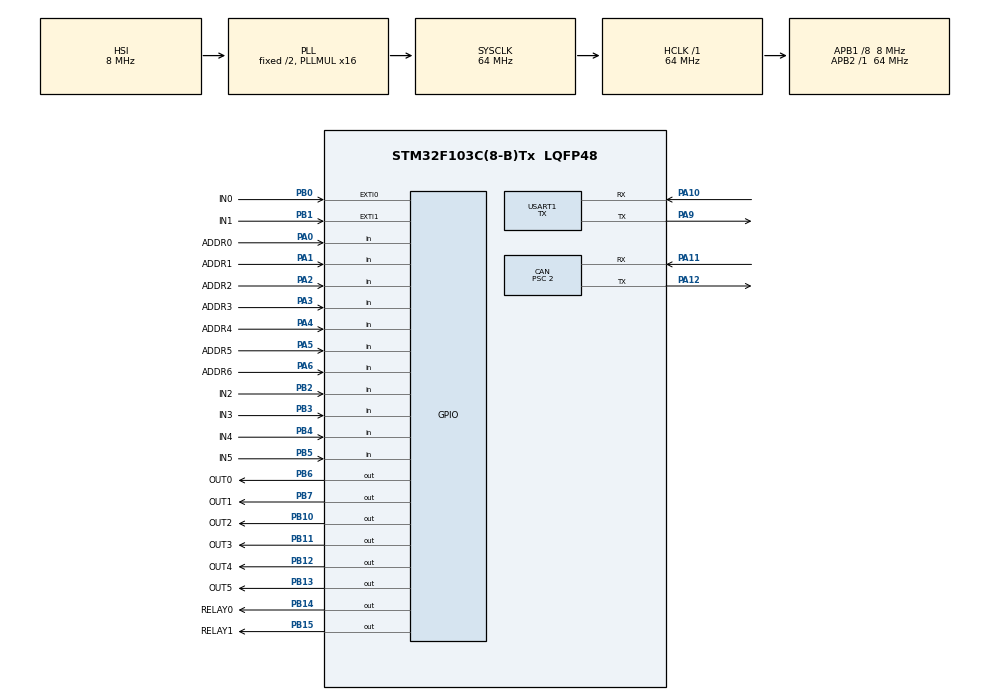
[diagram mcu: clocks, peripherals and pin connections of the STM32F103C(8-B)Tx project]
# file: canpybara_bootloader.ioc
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CAN.ABOM=ENABLE
CAN.BS1=CAN_BS1_6TQ
CAN.BS2=CAN_BS2_1TQ
CAN.CalculateTimeBit=2000
CAN.CalculateTimeQuantum=250.0
CAN.Prescaler=2
IWDG.Prescaler=IWDG_PRESCALER_16
Mcu.Family=STM32F1
Mcu.Name=STM32F103C(8-B)Tx
Mcu.Package=LQFP48
NVIC.CAN1_RX1_IRQn=true\:0\:0\:false\:false\:true\:true\:true
NVIC.CAN1_SCE_IRQn=true\:0\:0\:false\:false\:true\:true\:true
NVIC.EXTI0_IRQn=true\:0\:0\:false\:false\:true\:true\:true
NVIC.EXTI1_IRQn=true\:0\:0\:false\:false\:true\:true\:true
NVIC.PriorityGroup=NVIC_PRIORITYGROUP_4
NVIC.RCC_IRQn=true\:0\:0\:false\:false\:true\:true\:false
NVIC.USB_HP_CAN1_TX_IRQn=true\:0\:0\:false\:false\:true\:true\:true
NVIC.USB_LP_CAN1_RX0_IRQn=true\:0\:0\:false\:false\:true\:true\:true
PA0-WKUP.GPIO_Label=ADDR0
PA0-WKUP.GPIO_PuPd=GPIO_PULLUP
PA0-WKUP.Signal=GPIO_Input
PA1.GPIO_Label=ADDR1
PA1.GPIO_PuPd=GPIO_PULLUP
PA1.Signal=GPIO_Input
PA10.Mode=Asynchronous
PA10.Signal=USART1_RX
PA11.Mode=Master
PA11.Signal=CAN_RX
PA12.Mode=Master
PA12.Signal=CAN_TX
PA13.Mode=Serial_Wire
PA13.Signal=SYS_JTMS-SWDIO
PA14.Mode=Serial_Wire
PA14.Signal=SYS_JTCK-SWCLK
PA2.GPIO_Label=ADDR2
PA2.GPIO_PuPd=GPIO_PULLUP
PA2.Signal=GPIO_Input
PA3.GPIO_Label=ADDR3
PA3.GPIO_PuPd=GPIO_PULLUP
PA3.Signal=GPIO_Input
PA4.GPIO_Label=ADDR4
PA4.GPIO_PuPd=GPIO_PULLUP
PA4.Signal=GPIO_Input
PA5.GPIO_Label=ADDR5
PA5.GPIO_PuPd=GPIO_PULLUP
PA5.Signal=GPIO_Input
PA6.GPIO_Label=ADDR6
PA6.GPIO_PuPd=GPIO_PULLUP
PA6.Signal=GPIO_Input
PA9.Mode=Asynchronous
PA9.Signal=USART1_TX
PB0.GPIO_Label=IN0
PB0.GPIO_ModeDefaultEXTI=GPIO_MODE_IT_FALLING
PB0.Signal=GPXTI0
PB1.GPIO_Label=IN1
PB1.GPIO_ModeDefaultEXTI=GPIO_MODE_IT_FALLING
PB1.Signal=GPXTI1
PB10.GPIO_Label=OUT2
PB10.Signal=GPIO_Output
PB11.GPIO_Label=OUT3
PB11.Signal=GPIO_Output
PB12.GPIO_Label=OUT4
PB12.Signal=GPIO_Output
PB13.GPIO_Label=OUT5
PB13.Signal=GPIO_Output
PB14.GPIO_Label=RELAY0
PB14.Signal=GPIO_Output
PB15.GPIO_Label=RELAY1
PB15.Signal=GPIO_Output
PB2.GPIO_Label=IN2
PB2.Signal=GPIO_Input
PB3.GPIO_Label=IN3
PB3.Signal=GPIO_Input
PB4.GPIO_Label=IN4
PB4.Signal=GPIO_Input
PB5.GPIO_Label=IN5
PB5.Signal=GPIO_Input
PB6.GPIO_Label=OUT0
PB6.Signal=GPIO_Output
PB7.GPIO_Label=OUT1
PB7.Signal=GPIO_Output
PB8.Signal=I2C1_SCL
PB9.Signal=I2C1_SDA
PD0-OSC_IN.Mode=HSE-External-Oscillator
PD0-OSC_IN.Signal=RCC_OSC_IN
PD1-OSC_OUT.Mode=HSE-External-Oscillator
PD1-OSC_OUT.Signal=RCC_OSC_OUT
ProjectManager.HeapSize=0x200
ProjectManager.StackSize=0x400
ProjectManager.TargetToolchain=Makefile
RCC.AHBFreq_Value=64000000
RCC.APB1CLKDivider=RCC_HCLK_DIV8
RCC.APB1Freq_Value=8000000
RCC.APB1TimFreq_Value=16000000
RCC.APB2Freq_Value=64000000
RCC.APB2TimFreq_Value=64000000
RCC.HCLKFreq_Value=64000000
RCC.PLLMUL=RCC_PLL_MUL16
RCC.SYSCLKFreq_VALUE=64000000
RCC.SYSCLKSource=RCC_SYSCLKSOURCE_PLLCLK
RCC.USBFreq_Value=64000000
USART1.Mode=MODE_TX
USART1.VirtualMode=VM_ASYNC
VP_IWDG_VS_IWDG.Mode=IWDG_Activate
board=custom

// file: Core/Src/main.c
/* USER CODE BEGIN Header */
/**
  ******************************************************************************
  * @file           : main.c
  * @brief          : Main program body
  ******************************************************************************
  * @attention
  *
  * <h2><center>&copy; Copyright (c) 2020 STMicroelectronics.
  * All rights reserved.</center></h2>
  *
  * This software component is licensed by ST under BSD 3-Clause license,
  * the "License"; You may not use this file except in compliance with the
  * License. You may obtain a copy of the License at:
  *                        opensource.org/licenses/BSD-3-Clause
  *
  ******************************************************************************
  */
/* USER CODE END Header */

#include "main.h"

/* USER CODE BEGIN Includes */

#include "logger.h"
#include "can.h"
#include "bootloader.h"

/* USER CODE END Includes */

CAN_HandleTypeDef hcan;

IWDG_HandleTypeDef hiwdg;

UART_HandleTypeDef huart1;

/* USER CODE BEGIN PV */
/* Private variables ---------------------------------------------------------*/

/* USER CODE END PV */

void SystemClock_Config(void);
static void MX_GPIO_Init(void);
static void MX_CAN_Init(void);
static void MX_USART1_UART_Init(void);
static void MX_IWDG_Init(void);
/* USER CODE BEGIN PFP */
/* Private function prototypes -----------------------------------------------*/

/* USER CODE END PFP */

int main(void)
{

  /* MCU Configuration--------------------------------------------------------*/

  /* Reset of all peripherals, Initializes the Flash interface and the Systick. */
  HAL_Init();

  /* Configure the system clock */
  SystemClock_Config();

  /* Initialize all configured peripherals */
  MX_GPIO_Init();
  MX_CAN_Init();
  MX_USART1_UART_Init();
  MX_IWDG_Init();
  /* USER CODE BEGIN 2 */

  LOG_BOOT();

  canpybara_can_init();

  HAL_Delay(1000);

  canpybara_bootloader_send_discovery();
  /* USER CODE END 2 */

  /* Infinite loop */
  /* USER CODE BEGIN WHILE */
  for(;;)
  {
    HAL_IWDG_Refresh(&hiwdg);
    __asm__("WFI");

    canpybara_bootloader_loop();
    /* USER CODE END WHILE */

  }
}

void SystemClock_Config(void)
{
  RCC_OscInitTypeDef RCC_OscInitStruct = {0};
  RCC_ClkInitTypeDef RCC_ClkInitStruct = {0};

  /** Initializes the CPU, AHB and APB busses clocks
  */
  RCC_OscInitStruct.OscillatorType = RCC_OSCILLATORTYPE_HSI|RCC_OSCILLATORTYPE_LSI;
  RCC_OscInitStruct.HSIState = RCC_HSI_ON;
  RCC_OscInitStruct.HSICalibrationValue = RCC_HSICALIBRATION_DEFAULT;
  RCC_OscInitStruct.LSIState = RCC_LSI_ON;
  RCC_OscInitStruct.PLL.PLLState = RCC_PLL_ON;
  RCC_OscInitStruct.PLL.PLLSource = RCC_PLLSOURCE_HSI_DIV2;
  RCC_OscInitStruct.PLL.PLLMUL = RCC_PLL_MUL16;
  if (HAL_RCC_OscConfig(&RCC_OscInitStruct) != HAL_OK)
  {
    Error_Handler();
  }
  /** Initializes the CPU, AHB and APB busses clocks
  */
  RCC_ClkInitStruct.ClockType = RCC_CLOCKTYPE_HCLK|RCC_CLOCKTYPE_SYSCLK
                              |RCC_CLOCKTYPE_PCLK1|RCC_CLOCKTYPE_PCLK2;
  RCC_ClkInitStruct.SYSCLKSource = RCC_SYSCLKSOURCE_PLLCLK;
  RCC_ClkInitStruct.AHBCLKDivider = RCC_SYSCLK_DIV1;
  RCC_ClkInitStruct.APB1CLKDivider = RCC_HCLK_DIV8;
  RCC_ClkInitStruct.APB2CLKDivider = RCC_HCLK_DIV1;

  if (HAL_RCC_ClockConfig(&RCC_ClkInitStruct, FLASH_LATENCY_2) != HAL_OK)
  {
    Error_Handler();
  }
}

static void MX_CAN_Init(void)
{

  hcan.Instance = CAN1;
  hcan.Init.Prescaler = 2;
  hcan.Init.Mode = CAN_MODE_NORMAL;
  hcan.Init.SyncJumpWidth = CAN_SJW_1TQ;
  hcan.Init.TimeSeg1 = CAN_BS1_6TQ;
  hcan.Init.TimeSeg2 = CAN_BS2_1TQ;
  hcan.Init.TimeTriggeredMode = DISABLE;
  hcan.Init.AutoBusOff = ENABLE;
  hcan.Init.AutoWakeUp = DISABLE;
  hcan.Init.AutoRetransmission = DISABLE;
  hcan.Init.ReceiveFifoLocked = DISABLE;
  hcan.Init.TransmitFifoPriority = DISABLE;
  if (HAL_CAN_Init(&hcan) != HAL_OK)
  {
    Error_Handler();
  }

}

static void MX_IWDG_Init(void)
{

  hiwdg.Instance = IWDG;
  hiwdg.Init.Prescaler = IWDG_PRESCALER_16;
  hiwdg.Init.Reload = 4095;
  if (HAL_IWDG_Init(&hiwdg) != HAL_OK)
  {
    Error_Handler();
  }

}

static void MX_USART1_UART_Init(void)
{

  huart1.Instance = USART1;
  huart1.Init.BaudRate = 115200;
  huart1.Init.WordLength = UART_WORDLENGTH_8B;
  huart1.Init.StopBits = UART_STOPBITS_1;
  huart1.Init.Parity = UART_PARITY_NONE;
  huart1.Init.Mode = UART_MODE_TX;
  huart1.Init.HwFlowCtl = UART_HWCONTROL_NONE;
  huart1.Init.OverSampling = UART_OVERSAMPLING_16;
  if (HAL_UART_Init(&huart1) != HAL_OK)
  {
    Error_Handler();
  }

}

static void MX_GPIO_Init(void)
{
  GPIO_InitTypeDef GPIO_InitStruct = {0};

  /* GPIO Ports Clock Enable */
  __HAL_RCC_GPIOD_CLK_ENABLE();
  __HAL_RCC_GPIOA_CLK_ENABLE();
  __HAL_RCC_GPIOB_CLK_ENABLE();

  /*Configure GPIO pin Output Level */
  HAL_GPIO_WritePin(GPIOB, OUT2_Pin|OUT3_Pin|OUT4_Pin|OUT5_Pin
                          |RELAY0_Pin|RELAY1_Pin|OUT0_Pin|OUT1_Pin, GPIO_PIN_RESET);

  /*Configure GPIO pins : ADDR0_Pin ADDR1_Pin ADDR2_Pin ADDR3_Pin
                           ADDR4_Pin ADDR5_Pin ADDR6_Pin */
  GPIO_InitStruct.Pin = ADDR0_Pin|ADDR1_Pin|ADDR2_Pin|ADDR3_Pin
                          |ADDR4_Pin|ADDR5_Pin|ADDR6_Pin;
  GPIO_InitStruct.Mode = GPIO_MODE_INPUT;
  GPIO_InitStruct.Pull = GPIO_PULLUP;
  HAL_GPIO_Init(GPIOA, &GPIO_InitStruct);

  /*Configure GPIO pins : IN0_Pin IN1_Pin */
  GPIO_InitStruct.Pin = IN0_Pin|IN1_Pin;
  GPIO_InitStruct.Mode = GPIO_MODE_IT_FALLING;
  GPIO_InitStruct.Pull = GPIO_NOPULL;
  HAL_GPIO_Init(GPIOB, &GPIO_InitStruct);

  /*Configure GPIO pins : IN2_Pin IN3_Pin IN4_Pin IN5_Pin */
  GPIO_InitStruct.Pin = IN2_Pin|IN3_Pin|IN4_Pin|IN5_Pin;
  GPIO_InitStruct.Mode = GPIO_MODE_INPUT;
  GPIO_InitStruct.Pull = GPIO_NOPULL;
  HAL_GPIO_Init(GPIOB, &GPIO_InitStruct);

  /*Configure GPIO pins : OUT2_Pin OUT3_Pin OUT4_Pin OUT5_Pin
                           RELAY0_Pin RELAY1_Pin OUT0_Pin OUT1_Pin */
  GPIO_InitStruct.Pin = OUT2_Pin|OUT3_Pin|OUT4_Pin|OUT5_Pin
                          |RELAY0_Pin|RELAY1_Pin|OUT0_Pin|OUT1_Pin;
  GPIO_InitStruct.Mode = GPIO_MODE_OUTPUT_PP;
  GPIO_InitStruct.Pull = GPIO_NOPULL;
  GPIO_InitStruct.Speed = GPIO_SPEED_FREQ_LOW;
  HAL_GPIO_Init(GPIOB, &GPIO_InitStruct);

  /*Configure GPIO pins : PB8 PB9 */
  GPIO_InitStruct.Pin = GPIO_PIN_8|GPIO_PIN_9;
  GPIO_InitStruct.Mode = GPIO_MODE_AF_OD;
  GPIO_InitStruct.Speed = GPIO_SPEED_FREQ_HIGH;
  HAL_GPIO_Init(GPIOB, &GPIO_InitStruct);

  /*Configure peripheral I/O remapping */
  __HAL_AFIO_REMAP_I2C1_ENABLE();

  /* EXTI interrupt init*/
  HAL_NVIC_SetPriority(EXTI0_IRQn, 0, 0);
  HAL_NVIC_EnableIRQ(EXTI0_IRQn);

  HAL_NVIC_SetPriority(EXTI1_IRQn, 0, 0);
  HAL_NVIC_EnableIRQ(EXTI1_IRQn);

}

void Error_Handler(void)
{
  /* USER CODE BEGIN Error_Handler_Debug */

  LOG("ERROR HANDLER");

  /* User can add his own implementation to report the HAL error return state */
  while(1)
  {
  }
  /* USER CODE END Error_Handler_Debug */
}

/************************ (C) COPYRIGHT STMicroelectronics *****END OF FILE****/
